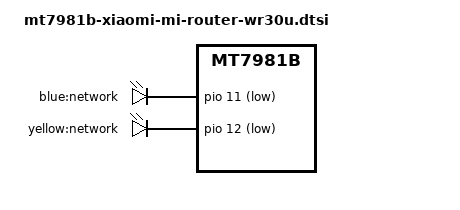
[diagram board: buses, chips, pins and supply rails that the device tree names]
// SPDX-License-Identifier: GPL-2.0-or-later OR MIT

/dts-v1/;
#include "mt7981b-xiaomi-mi-router-common.dtsi"


&gmac0 {
	nvmem-cells = <&macaddr_factory_4 (-1)>;
};

&leds {
	led_network_blue {
		label = "blue:network";
		gpios = <&pio 11 GPIO_ACTIVE_LOW>;
	};

	led_network_yellow {
		label = "yellow:network";
		gpios = <&pio 12 GPIO_ACTIVE_LOW>;
	};
};
